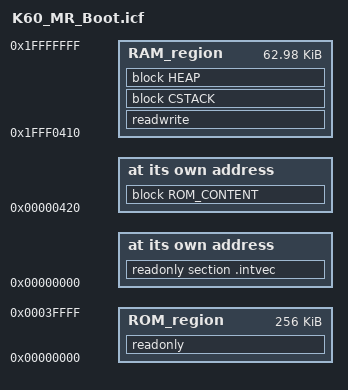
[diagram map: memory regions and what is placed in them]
/*###ICF### Section handled by ICF editor, don't touch! ****/
/*-Editor annotation file-*/
/* IcfEditorFile="$TOOLKIT_DIR$\config\ide\IcfEditor\cortex_v1_0.xml" */
/*-Specials-*/
define symbol __ICFEDIT_intvec_start__ = 0x00000000;
/*-Memory Regions-*/
define symbol __ICFEDIT_region_ROM_start__ = 0x00000000;
define symbol __ICFEDIT_region_ROM_end__   = 0x0003FFFF;
//define symbol __ICFEDIT_region_RAM_start__ = 0x20000000;
//define symbol __ICFEDIT_region_RAM_end__   = 0x20010000;
define symbol __ICFEDIT_region_RAM_start__ = 0x1FFF0410;
define symbol __ICFEDIT_region_RAM_end__   = 0x1FFFFFFF;
/*-Sizes-*/
define symbol __ICFEDIT_size_cstack__ = 0x1000;
define symbol __ICFEDIT_size_heap__   = 0x800;
/**** End of ICF editor section. ###ICF###*/

define symbol __FlashConfig_start__	= 0x00000400;
define symbol __FlashConfig_end__  	= 0x0000040f;

define exported symbol __VECTOR_TABLE = 0x00000000;
define exported symbol __VECTOR_RAM = 0x1fff0000;

define exported symbol __BOOT_STACK_ADDRESS = __ICFEDIT_region_RAM_end__ - 8;	//0x2000FFF8;

define exported symbol ROM_address = 0x00000000;
define exported symbol __VECTOR_RAM2 = 0x1FFF0000;

define memory mem with size = 4G;
define region ROM_region = mem:[from __ICFEDIT_region_ROM_start__ to __ICFEDIT_region_ROM_end__];
define region RAM_region = mem:[from __ICFEDIT_region_RAM_start__ to __ICFEDIT_region_RAM_end__];

define block CSTACK    with alignment = 8, size = __ICFEDIT_size_cstack__   { };
define block HEAP      with alignment = 8, size = __ICFEDIT_size_heap__     { };

define block ROM_CONTENT with fixed order
{
    ro data,
    ro code
};

initialize by copy { readwrite };
do not initialize  { section .noinit };

place at address mem:__ICFEDIT_intvec_start__ { readonly section .intvec };
place at address mem:0x420 { block ROM_CONTENT };
place in ROM_region   { readonly };
place in RAM_region   { readwrite, block CSTACK, block HEAP };
